# ESP32-S2 register map
Vendor: ESPRESSIF SYSTEMS (SHANGHAI) CO., LTD.; Series: ESP32 S-Series; File version: 20
CPU: Xtensa LX7 r0p0, little endian, no MPU, no FPU, 0 interrupt priority bits
Address unit: 32 bits
Registers are 32-bit, read-write, reset 0x0 unless marked. A register's access mark holds for its fields unless they carry their own. Offsets are from the block's base; [hi:lo] are bit positions; {n}, {i} and the like mark numbered series.

## RTC_CNTL — Real-Time Clock Control
Base 0x3F408000
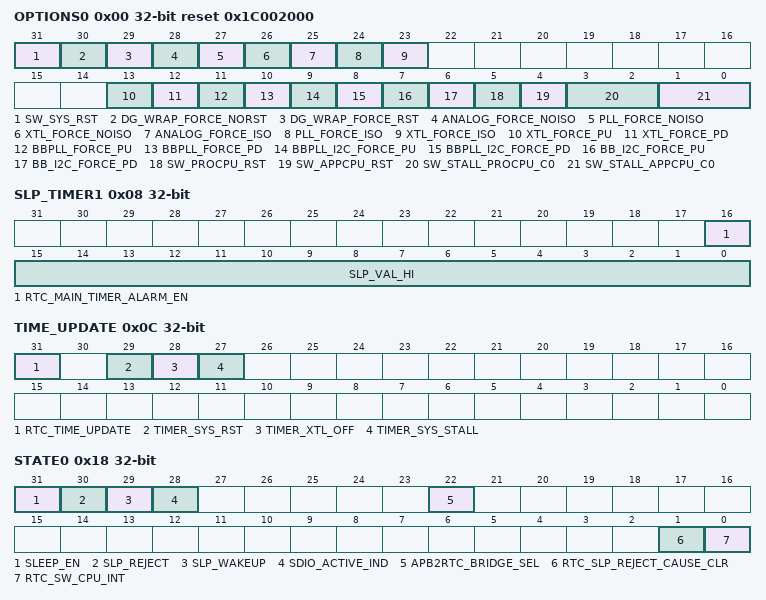
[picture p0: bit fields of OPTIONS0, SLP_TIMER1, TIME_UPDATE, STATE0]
0x00 OPTIONS0 access per field reset 0x1C002000 — Sets the power options of crystal and PLL clocks, and initiates reset by software
  [31] SW_SYS_RST wo — Set this bit to reset the system via SW.
  [30] DG_WRAP_FORCE_NORST rw — Set this bit to disable force reset to digital system in deep-sleep.
  [29] DG_WRAP_FORCE_RST rw — Set this bit to force reset the digital system in deep-sleep.
  [28] ANALOG_FORCE_NOISO rw
  [27] PLL_FORCE_NOISO rw
  [26] XTL_FORCE_NOISO rw
  [25] ANALOG_FORCE_ISO rw
  [24] PLL_FORCE_ISO rw
  [23] XTL_FORCE_ISO rw
  [13] XTL_FORCE_PU rw — Set this bit to FPU the crystal oscillator.
  [12] XTL_FORCE_PD rw — Set this bit to FPD the crystal oscillator.
  [11] BBPLL_FORCE_PU rw — Set this bit to FPU BB_PLL.
  [10] BBPLL_FORCE_PD rw — Set this bit to FPD BB_PLL.
  [9] BBPLL_I2C_FORCE_PU rw — Set this bit to FPU BB_PLL _I2C.
  [8] BBPLL_I2C_FORCE_PD rw — Set this bit to FPD BB_PLL _I2C.
  [7] BB_I2C_FORCE_PU rw — Set this bit to FPU BB_I2C.
  [6] BB_I2C_FORCE_PD rw — Set this bit to FPD BB_I2C.
  [5] SW_PROCPU_RST wo — Set this bit to reset the CPU by SW.
  [4] SW_APPCPU_RST wo — APP CPU SW reset. (Note, we don’t have APP CPU for ESP32-S2)
  [3:2] SW_STALL_PROCPU_C0 rw — When RTC_CNTL_REG_SW_STALL_PROCPU_C1 is configured to 0x21, setting this bit to 0x2 stalls the CPU by SW.
  [1:0] SW_STALL_APPCPU_C0 rw — {reg_sw_stall_appcpu_c1[5:0] , reg_sw_stall_appcpu_c0[1:0]} == 0x86 will stall APP CPU
0x04 SLP_TIMER0 — RTC timer threshold register 0
  [31:0] SLP_VAL_LO — Sets the lower 32 bits of the trigger threshold for the RTC timer.
0x08 SLP_TIMER1 access per field — RTC timer threshold register 1
  [16] RTC_MAIN_TIMER_ALARM_EN wo — Sets this bit to enable the timer alarm.
  [15:0] SLP_VAL_HI rw — Sets the higher 16 bits of the trigger threshold for the RTC timer.
0x0C TIME_UPDATE access per field — RTC timer update control register
  [31] RTC_TIME_UPDATE wo — Selects the triggering condition for the RTC timer. See details in Table 1-2.
  [29] TIMER_SYS_RST rw — Selects the triggering condition for the RTC timer. See details in Table 1-2.
  [28] TIMER_XTL_OFF rw — Selects the triggering condition for the RTC timer. See details in Table 1-2.
  [27] TIMER_SYS_STALL rw — Selects the triggering condition for the RTC timer. See details in Table 1-2.
0x10 TIME_LOW0 ro — Stores the lower 32 bits of RTC timer 0.
  [31:0] RTC_TIMER_VALUE0_LOW
0x14 TIME_HIGH0 ro — Stores the higher 16 bits of RTC timer 0
  [15:0] RTC_TIMER_VALUE0_HIGH — Stores the higher 16 bits of RTC timer 0.
0x18 STATE0 access per field — Configures the sleep / reject / wakeup state
  [31] SLEEP_EN rw — Sends the chip to sleep.
  [30] SLP_REJECT rw — Sleep reject bit.
  [29] SLP_WAKEUP rw — Sleep wakeup bit.
  [28] SDIO_ACTIVE_IND ro — Indicates the SDIO is active.
  [22] APB2RTC_BRIDGE_SEL rw — 1: APB to RTC using bridge 0: APB to RTC using sync
  [1] RTC_SLP_REJECT_CAUSE_CLR wo — Clears the RTC reject-to-sleep cause.
  [0] RTC_SW_CPU_INT wo — Sends a SW RTC interrupt to CPU.
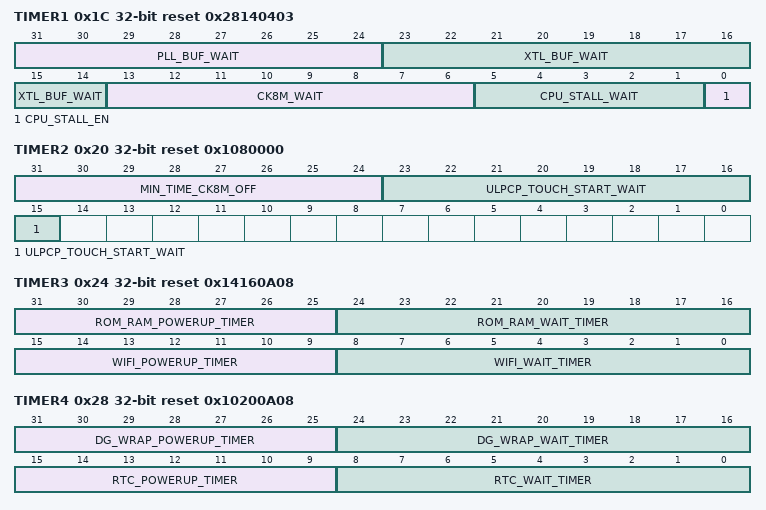
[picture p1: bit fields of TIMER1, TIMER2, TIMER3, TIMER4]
0x1C TIMER1 reset 0x28140403 — Configures CPU stall options
  [31:24] PLL_BUF_WAIT — Sets the PLL waiting cycle (using the RTC slow clock).
  [23:14] XTL_BUF_WAIT — Sets the XTAL waiting cycle (using the RTC slow clock).
  [13:6] CK8M_WAIT — Sets the 8 MHz clock waiting (using the RTC slow clock).
  [5:1] CPU_STALL_WAIT — Sets the CPU stall waiting cycle (using the RTC fast clock).
  [0] CPU_STALL_EN — Enables CPU stalling.
0x20 TIMER2 reset 0x1080000 — Configures RTC slow clock and touch controller
  [31:24] MIN_TIME_CK8M_OFF — Sets the minimal cycle for 8 MHz clock (using the RTC slow clock) when powered down.
  [23:15] ULPCP_TOUCH_START_WAIT — Sets the waiting cycle (using the RTC slow clock) before the ULP co-processor / touch controller start to work.
0x24 TIMER3 reset 0x14160A08 — configure some wait time for power on
  [31:25] ROM_RAM_POWERUP_TIMER, [24:16] ROM_RAM_WAIT_TIMER, [15:9] WIFI_POWERUP_TIMER, [8:0] WIFI_WAIT_TIMER
0x28 TIMER4 reset 0x10200A08 — configure some wait time for power on
  [31:25] DG_WRAP_POWERUP_TIMER, [24:16] DG_WRAP_WAIT_TIMER, [15:9] RTC_POWERUP_TIMER, [8:0] RTC_WAIT_TIMER
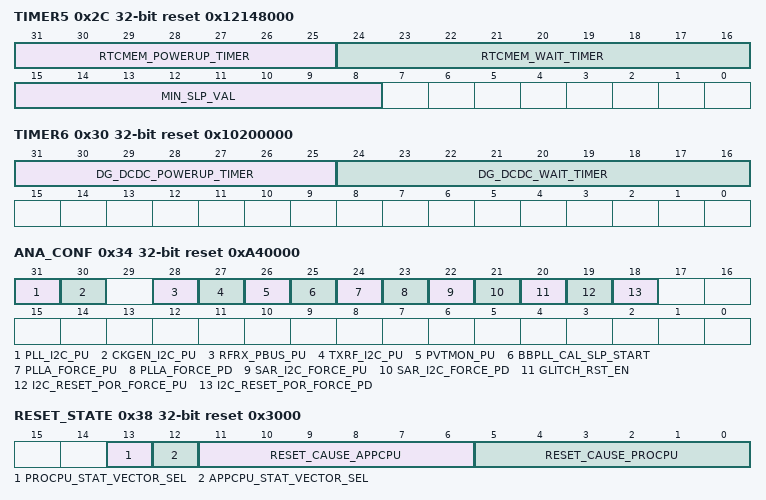
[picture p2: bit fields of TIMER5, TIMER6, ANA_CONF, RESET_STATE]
0x2C TIMER5 reset 0x12148000 — Configures the minimal sleep cycles
  [31:25] RTCMEM_POWERUP_TIMER
  [24:16] RTCMEM_WAIT_TIMER
  [15:8] MIN_SLP_VAL — Sets the minimal sleep cycles (using the RTC slow clock).
0x30 TIMER6 reset 0x10200000 — Configure minimal sleep cycles register
  [31:25] DG_DCDC_POWERUP_TIMER, [24:16] DG_DCDC_WAIT_TIMER
0x34 ANA_CONF reset 0xA40000 — Configures the power options for I2C and PLLA
  [31] PLL_I2C_PU — 1. PLL_I2C power up ,otherwise power down
  [30] CKGEN_I2C_PU — 1: CKGEN_I2C power up , otherwise power down
  [28] RFRX_PBUS_PU — 1: RFRX_PBUS power up , otherwise power down
  [27] TXRF_I2C_PU — 1: TXRF_I2C power up , otherwise power down
  [26] PVTMON_PU — 1: PVTMON power up , otherwise power down
  [25] BBPLL_CAL_SLP_START — start BBPLL calibration during sleep
  [24] PLLA_FORCE_PU — Sets this bit to FPU the PLLA.
  [23] PLLA_FORCE_PD — Sets this bit to FPD the PLLA.
  [22] SAR_I2C_FORCE_PU — Sets this bit to FPU the SAR_I2C.
  [21] SAR_I2C_FORCE_PD — Sets this bit to FPD the SAR_I2C.
  [20] GLITCH_RST_EN — Set this bit to enable a reset when the system detects a glitch.
  [19] I2C_RESET_POR_FORCE_PU — SLEEP_I2CPOR force pu
  [18] I2C_RESET_POR_FORCE_PD — SLEEP_I2CPOR force pd
0x38 RESET_STATE access per field reset 0x3000 — Indicates the CPU reset source. For more information about the reset cause, please refer to Table ef{table:resetreasons} in Chapter ef{module:ResetandClock} extit{ ameref{module:ResetandClock}}.
  [13] PROCPU_STAT_VECTOR_SEL rw — Selects the CPU state vector.
  [12] APPCPU_STAT_VECTOR_SEL rw — APP CPU state vector sel
  [11:6] RESET_CAUSE_APPCPU ro — reset cause of APP CPU
  [5:0] RESET_CAUSE_PROCPU ro — Stores the CPU reset cause.
0x3C WAKEUP_STATE reset 0x60000 — Wakeup bitmap enabling register
  [31:15] RTC_WAKEUP_ENA — Enables the wakeup bitmap.
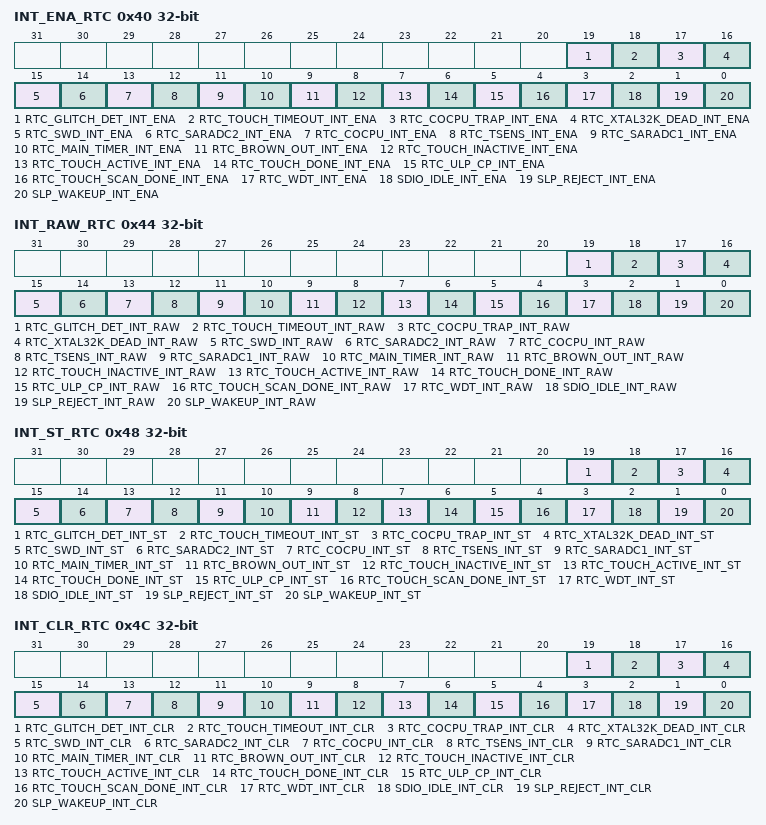
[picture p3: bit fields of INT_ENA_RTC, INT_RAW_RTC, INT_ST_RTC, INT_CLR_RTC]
0x40 INT_ENA_RTC — RTC interrupt enabling register
  [19] RTC_GLITCH_DET_INT_ENA — Enables interruption when a glitch is detected.
  [18] RTC_TOUCH_TIMEOUT_INT_ENA — Enables interruption when touch sensor times out.
  [17] RTC_COCPU_TRAP_INT_ENA — Enables interruption when the ULP-RISCV is trapped.
  [16] RTC_XTAL32K_DEAD_INT_ENA — Enables interruption when the 32 kHz crystal is dead.
  [15] RTC_SWD_INT_ENA — Enables the super watchdog interrupt.
  [14] RTC_SARADC2_INT_ENA — Enables the SAR ADC 2 interrupt.
  [13] RTC_COCPU_INT_ENA — Enables the ULP-RISCV interrupt.
  [12] RTC_TSENS_INT_ENA — Enables the touch sensor interrupt.
  [11] RTC_SARADC1_INT_ENA — Enables the SAR ADC 1 interrupt.
  [10] RTC_MAIN_TIMER_INT_ENA — Enables the RTC main timer interrupt.
  [9] RTC_BROWN_OUT_INT_ENA — Enables the brown out interrupt.
  [8] RTC_TOUCH_INACTIVE_INT_ENA — Enables interruption when a touch is released.
  [7] RTC_TOUCH_ACTIVE_INT_ENA — Enables interruption when a touch is detected.
  [6] RTC_TOUCH_DONE_INT_ENA — Enables interruption upon the completion of a single touch.
  [5] RTC_ULP_CP_INT_ENA — Enables the ULP co-processor interrupt.
  [4] RTC_TOUCH_SCAN_DONE_INT_ENA — Enables interruption upon the completion of a touch scanning.
  [3] RTC_WDT_INT_ENA — Enables the RTC watchdog interrupt.
  [2] SDIO_IDLE_INT_ENA — Enables interruption when the SDIO idles.
  [1] SLP_REJECT_INT_ENA — Enables interruption when the chip rejects to go to sleep.
  [0] SLP_WAKEUP_INT_ENA — Enables interruption when the chip wakes up from sleep.
0x44 INT_RAW_RTC ro — RTC interrupt raw register
  [19] RTC_GLITCH_DET_INT_RAW — Stores the raw interrupt triggered when a glitch is detected.
  [18] RTC_TOUCH_TIMEOUT_INT_RAW — Stores the raw interrupt triggered when touch sensor times out.
  [17] RTC_COCPU_TRAP_INT_RAW — Stores the raw interrupt triggered when the ULP-RISCV is trapped.
  [16] RTC_XTAL32K_DEAD_INT_RAW — Stores the raw interrupt triggered when the 32 kHz crystal is dead.
  [15] RTC_SWD_INT_RAW — Stores the raw super watchdog interrupt.
  [14] RTC_SARADC2_INT_RAW — Stores the raw SAR ADC 2 interrupt.
  [13] RTC_COCPU_INT_RAW — Stores the raw ULP-RISCV interrupt.
  [12] RTC_TSENS_INT_RAW — Stores the raw touch sensor interrupt.
  [11] RTC_SARADC1_INT_RAW — Stores the raw SAR ADC 1 interrupt.
  [10] RTC_MAIN_TIMER_INT_RAW — Stores the raw RTC main timer interrupt.
  [9] RTC_BROWN_OUT_INT_RAW — Stores the raw brown out interrupt.
  [8] RTC_TOUCH_INACTIVE_INT_RAW — Stores the raw interrupt triggered when a touch is released.
  [7] RTC_TOUCH_ACTIVE_INT_RAW — Stores the raw interrupt triggered when a touch is detected.
  [6] RTC_TOUCH_DONE_INT_RAW — Stores the raw interrupt triggered upon the completion of a single touch.
  [5] RTC_ULP_CP_INT_RAW — Stores the raw ULP co-processor interrupt.
  [4] RTC_TOUCH_SCAN_DONE_INT_RAW — Stores the raw interrupt triggered upon the completion of a touch scanning.
  [3] RTC_WDT_INT_RAW — Stores the raw RTC watchdog interrupt.
  [2] SDIO_IDLE_INT_RAW — Stores the raw interrupt triggered when the SDIO idles.
  [1] SLP_REJECT_INT_RAW — Stores the raw interrupt triggered when the chip rejects to go to sleep.
  [0] SLP_WAKEUP_INT_RAW — Stores the raw interrupt triggered when the chip wakes up from sleep.
0x48 INT_ST_RTC ro — RTC interrupt state register
  [19] RTC_GLITCH_DET_INT_ST — Stores the status of the interrupt triggered when a glitch is detected.
  [18] RTC_TOUCH_TIMEOUT_INT_ST — Stores the status of the interrupt triggered when touch sensor times out.
  [17] RTC_COCPU_TRAP_INT_ST — Stores the status of the interrupt triggered when the ULP-RISCV is trapped.
  [16] RTC_XTAL32K_DEAD_INT_ST — Stores the status of the interrupt triggered when the 32 kHz crystal is dead.
  [15] RTC_SWD_INT_ST — Stores the status of the super watchdog interrupt.
  [14] RTC_SARADC2_INT_ST — Stores the status of the SAR ADC 2 interrupt.
  [13] RTC_COCPU_INT_ST — Stores the status of the ULP-RISCV interrupt.
  [12] RTC_TSENS_INT_ST — Stores the status of the touch sensor interrupt.
  [11] RTC_SARADC1_INT_ST — Stores the status of the SAR ADC 1 interrupt.
  [10] RTC_MAIN_TIMER_INT_ST — Stores the status of the RTC main timer interrupt.
  [9] RTC_BROWN_OUT_INT_ST — Stores the status of the brown out interrupt.
  [8] RTC_TOUCH_INACTIVE_INT_ST — Stores the status of the interrupt triggered when a touch is released.
  [7] RTC_TOUCH_ACTIVE_INT_ST — Stores the status of the interrupt triggered when a touch is detected.
  [6] RTC_TOUCH_DONE_INT_ST — Stores the status of the interrupt triggered upon the completion of a single touch.
  [5] RTC_ULP_CP_INT_ST — Stores the status of the ULP co-processor interrupt.
  [4] RTC_TOUCH_SCAN_DONE_INT_ST — Stores the status of the interrupt triggered upon the completion of a touch scanning.
  [3] RTC_WDT_INT_ST — Stores the status of the RTC watchdog interrupt.
  [2] SDIO_IDLE_INT_ST — Stores the status of the interrupt triggered when the SDIO idles.
  [1] SLP_REJECT_INT_ST — Stores the status of the interrupt triggered when the chip rejects to go to sleep.
  [0] SLP_WAKEUP_INT_ST — Stores the status of the interrupt triggered when the chip wakes up from sleep.
0x4C INT_CLR_RTC wo — RTC interrupt clear register
  [19] RTC_GLITCH_DET_INT_CLR — Clears the interrupt triggered when a glitch is detected.
  [18] RTC_TOUCH_TIMEOUT_INT_CLR — Clears the interrupt triggered when touch sensor times out.
  [17] RTC_COCPU_TRAP_INT_CLR — Clears the interrupt triggered when the ULP-RISCV is trapped.
  [16] RTC_XTAL32K_DEAD_INT_CLR — Clears the interrupt triggered when the 32 kHz crystal is dead.
  [15] RTC_SWD_INT_CLR — Clears the super watchdog interrupt.
  [14] RTC_SARADC2_INT_CLR — Clears the SAR ADC 2 interrupt.
  [13] RTC_COCPU_INT_CLR — Clears the ULP-RISCV interrupt.
  [12] RTC_TSENS_INT_CLR — Clears the touch sensor interrupt.
  [11] RTC_SARADC1_INT_CLR — Clears the SAR ADC 1 interrupt.
  [10] RTC_MAIN_TIMER_INT_CLR — Clears the RTC main timer interrupt.
  [9] RTC_BROWN_OUT_INT_CLR — Clears the brown out interrupt.
  [8] RTC_TOUCH_INACTIVE_INT_CLR — Clears the interrupt triggered when a touch is released.
  [7] RTC_TOUCH_ACTIVE_INT_CLR — Clears the interrupt triggered when a touch is detected.
  [6] RTC_TOUCH_DONE_INT_CLR — Clears the interrupt triggered upon the completion of a single touch.
  [5] RTC_ULP_CP_INT_CLR — Enables the ULP co-processor interrupt.
  [4] RTC_TOUCH_SCAN_DONE_INT_CLR — Clears the interrupt triggered upon the completion of a touch scanning.
  [3] RTC_WDT_INT_CLR — Enables the RTC watchdog interrupt.
  [2] SDIO_IDLE_INT_CLR — Clears the interrupt triggered when the SDIO idles.
  [1] SLP_REJECT_INT_CLR — Clears the interrupt triggered when the chip rejects to go to sleep.
  [0] SLP_WAKEUP_INT_CLR — Clears the interrupt triggered when the chip wakes up from sleep.
{0x50+4i} STORE{i} (i=0..3) — Reservation register {i}
  [31:0] RTC_SCRATCH{i}
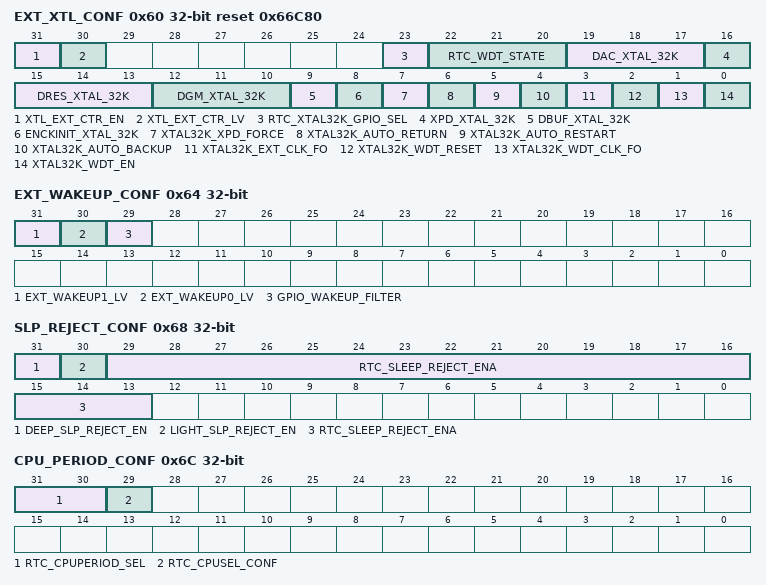
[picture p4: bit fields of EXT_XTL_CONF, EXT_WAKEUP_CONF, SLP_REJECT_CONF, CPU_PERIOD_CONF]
0x60 EXT_XTL_CONF access per field reset 0x66C80 — 32 kHz crystal oscillator configuration register
  [31] XTL_EXT_CTR_EN rw — Enables the GPIO to power down the crystal oscillator.
  [30] XTL_EXT_CTR_LV rw — 0: powers down XTAL at high level 1: powers down XTAL at low level
  [23] RTC_XTAL32K_GPIO_SEL rw — Selects the 32 kHz crystal clock. 0: selects the external 32 kHz clock. 1: selects clock from the RTC GPIO X32P_C.
  [22:20] RTC_WDT_STATE ro — Stores the status of the 32 kHz watchdog.
  [19:17] DAC_XTAL_32K rw
  [16] XPD_XTAL_32K rw
  [15:13] DRES_XTAL_32K rw
  [12:10] DGM_XTAL_32K rw — xtal_32k gm control
  [9] DBUF_XTAL_32K rw — 0: single-end buffer 1: differential buffer
  [8] ENCKINIT_XTAL_32K rw — Applies an internal clock to help the 32 kHz crystal to start.
  [7] XTAL32K_XPD_FORCE rw — Set 1 to allow the software to FPD the 32 kHz crystal. Set 0 to allow the FSM to FPD the 32 kHz crystal. (R/W)
  [6] XTAL32K_AUTO_RETURN rw — Set this bit to switch back to 32 kHz crystal when the 32 kHz crystal is restarted.
  [5] XTAL32K_AUTO_RESTART rw — Set this bit to restart the 32 kHz crystal automatically when the 32 kHz crystal is dead.
  [4] XTAL32K_AUTO_BACKUP rw — Set this bit to switch to the backup clock when the 32 kHz crystal is dead.
  [3] XTAL32K_EXT_CLK_FO rw — Set this bit to FPU the external clock of 32 kHz crystal.
  [2] XTAL32K_WDT_RESET rw — Set this bit to reset the 32 kHz crystal watchdog by SW.
  [1] XTAL32K_WDT_CLK_FO rw — Set this bit to FPU the 32 kHz crystal watchdog clock.
  [0] XTAL32K_WDT_EN rw — Set this bit to enable the 32 kHz crystal watchdog.
0x64 EXT_WAKEUP_CONF — GPIO wakeup configuration register
  [31] EXT_WAKEUP1_LV — 0: external wakeup 1 at low level 1: external wakeup 1 at high level
  [30] EXT_WAKEUP0_LV — 0: external wakeup 0 at low level 1: external wakeup 0 at high level
  [29] GPIO_WAKEUP_FILTER — Set this bit to enable the GPIO wakeup event filter.
0x68 SLP_REJECT_CONF — Configures sleep / reject options
  [31] DEEP_SLP_REJECT_EN — Set this bit to enable reject-to-deep-sleep.
  [30] LIGHT_SLP_REJECT_EN — Set this bit to enable reject-to-light-sleep.
  [29:13] RTC_SLEEP_REJECT_ENA — Set this bit to enable reject-to-sleep.
0x6C CPU_PERIOD_CONF — CPU sel option
  [31:30] RTC_CPUPERIOD_SEL
  [29] RTC_CPUSEL_CONF — CPU sel option
0x70 SDIO_ACT_CONF — configure sdio active register
  [31:22] SDIO_ACT_DNUM — configure sdio act dnum
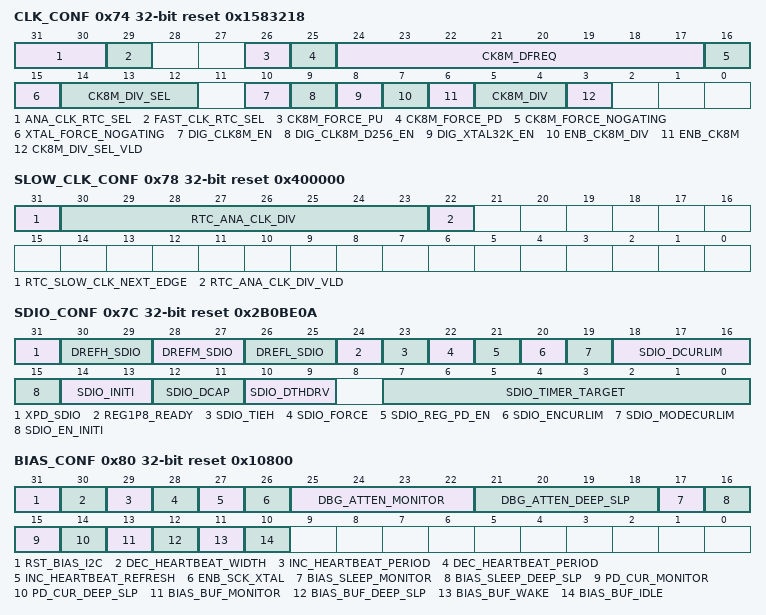
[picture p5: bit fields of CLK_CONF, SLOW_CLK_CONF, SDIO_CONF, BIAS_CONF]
0x74 CLK_CONF reset 0x1583218 — RTC clock configuration register
  [31:30] ANA_CLK_RTC_SEL — Set this bit to select the RTC slow clock. 0: 90K rtc_clk 1: 32k XTAL 2: 8md256.
  [29] FAST_CLK_RTC_SEL — Set this bit to select the RTC fast clock. 0: XTAL div 4, 1: CK8M.
  [26] CK8M_FORCE_PU — Set this bit to FPU the 8 MHz clock.
  [25] CK8M_FORCE_PD — Set this bit to FPD the 8 MHz clock.
  [24:17] CK8M_DFREQ
  [16] CK8M_FORCE_NOGATING — Set this bit to disable force gating to 8 MHz crystal during sleep.
  [15] XTAL_FORCE_NOGATING — Set this bit to force no gating to crystal during sleep
  [14:12] CK8M_DIV_SEL — Stores the 8 MHz divider, which is reg_ck8m_div_sel + 1
  [10] DIG_CLK8M_EN — Set this bit to enable 8 MHz clock for the digital core.
  [9] DIG_CLK8M_D256_EN — Set this bit to enable CK8M_D256_OUT clock for the digital core.
  [8] DIG_XTAL32K_EN — Set this bit to enable CK_XTAL_32K clock for the digital core.
  [7] ENB_CK8M_DIV — Selects the CK8M_D256_OUT. 1: CK8M 0: CK8M divided by 256.
  [6] ENB_CK8M — Set this bit to disable CK8M and CK8M_D256_OUT.
  [5:4] CK8M_DIV — Set the CK8M_D256_OUT divider. 00: divided by 128 01: divided by 256 10: divided by 512 11: divided by 1024.
  [3] CK8M_DIV_SEL_VLD — Synchronizes the reg_ck8m_div_sel. Not that you have to invalidate the bus before switching clock, and validate the new clock.
0x78 SLOW_CLK_CONF reset 0x400000 — RTC slow clock configuration register
  [31] RTC_SLOW_CLK_NEXT_EDGE
  [30:23] RTC_ANA_CLK_DIV — Set the rtc_clk divider.
  [22] RTC_ANA_CLK_DIV_VLD — Synchronizes the reg_rtc_ana_clk_div bus. Note that you have to invalidate the bus before switching clock, and validate the new clock.
0x7C SDIO_CONF access per field reset 0x2B0BE0A — configure vddsdio register
  [31] XPD_SDIO rw — SW option for XPD_VOOSDIO. Only active when reg_sdio_force = 1
  [30:29] DREFH_SDIO rw — SW option for DREFH_SDIO. Only active when reg_sdio_force = 1
  [28:27] DREFM_SDIO rw — SW option for DREFM_SDIO. Only active when reg_sdio_force = 1
  [26:25] DREFL_SDIO rw — SW option for DREFL_SDIO. Only active when reg_sdio_force = 1
  [24] REG1P8_READY ro — read only register for REG1P8_READY
  [23] SDIO_TIEH rw — SW option for SDIO_TIEH. Only active when reg_sdio_force = 1
  [22] SDIO_FORCE rw — 1: use SW option to control SDIO_REG 0: use state machine
  [21] SDIO_REG_PD_EN rw — power down SDIO_REG in sleep. Only active when reg_sdio_force = 0
  [20] SDIO_ENCURLIM rw — enable current limit
  [19] SDIO_MODECURLIM rw — select current limit mode
  [18:16] SDIO_DCURLIM rw — tune current limit threshold when tieh = 0. About 800mA/(8+d)
  [15] SDIO_EN_INITI rw — 0 to set init[1:0]=0
  [14:13] SDIO_INITI rw — add resistor from ldo output to ground. 0: no res 1: 6k 2: 4k 3: 2k
  [12:11] SDIO_DCAP rw — ability to prevent LDO from overshoot
  [10:9] SDIO_DTHDRV rw — Tieh = 1 mode drive ability. Initially set to 0 to limit charge current set to 3 after several us.
  [7:0] SDIO_TIMER_TARGET rw — timer count to apply reg_sdio_dcap after sdio power on
0x80 BIAS_CONF reset 0x10800 — configure power register
  [31] RST_BIAS_I2C
  [30] DEC_HEARTBEAT_WIDTH
  [29] INC_HEARTBEAT_PERIOD
  [28] DEC_HEARTBEAT_PERIOD
  [27] INC_HEARTBEAT_REFRESH
  [26] ENB_SCK_XTAL
  [25:22] DBG_ATTEN_MONITOR — DBG_ATTEN when rtc in monitor state
  [21:18] DBG_ATTEN_DEEP_SLP — DBG_ATTEN when rtc in sleep state
  [17] BIAS_SLEEP_MONITOR — bias_sleep when rtc in monitor state
  [16] BIAS_SLEEP_DEEP_SLP — bias_sleep when rtc in sleep_state
  [15] PD_CUR_MONITOR — xpd cur when rtc in monitor state
  [14] PD_CUR_DEEP_SLP — xpd cur when rtc in sleep_state
  [13] BIAS_BUF_MONITOR — open bias buf when rtc in monitor state
  [12] BIAS_BUF_DEEP_SLP — open bias buf when rtc in deep sleep
  [11] BIAS_BUF_WAKE — open bias buf when rtc in wakeup
  [10] BIAS_BUF_IDLE — open bias buf when system in active
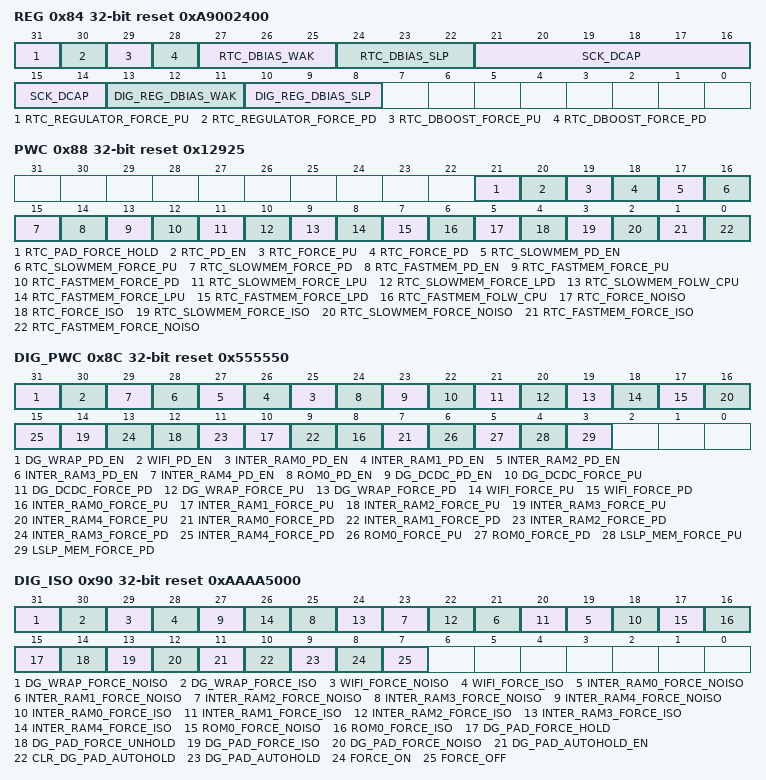
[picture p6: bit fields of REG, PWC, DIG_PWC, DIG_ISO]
0x84 REG reset 0xA9002400 — RTC/DIG regulator configuration register
  [31] RTC_REGULATOR_FORCE_PU — Set this bit to FPU the RTC_REG.
  [30] RTC_REGULATOR_FORCE_PD — Set this bit to FPD the RTC_REG, which means decreasing its voltage to 0.8 V or lower.
  [29] RTC_DBOOST_FORCE_PU — RTC_DBOOST force power up
  [28] RTC_DBOOST_FORCE_PD — RTC_DBOOST force power down
  [27:25] RTC_DBIAS_WAK — Configures the regulation factor for the low-power voltage regulator when the CPU is in active status.
  [24:22] RTC_DBIAS_SLP — Configures the regulation factor for the low-power voltage regulator when the CPU is in sleep status.
  [21:14] SCK_DCAP — Configures the frequency of the RTC clocks.
  [13:11] DIG_REG_DBIAS_WAK — Configures the regulation factor for the digital system voltage regulator when the CPU is in active status.
  [10:8] DIG_REG_DBIAS_SLP — Configures the regulation factor for the digital system voltage regulator when the CPU is in sleep status.
0x88 PWC reset 0x12925 — RTC power configuraiton register
  [21] RTC_PAD_FORCE_HOLD — Set this bit the force hold the RTC GPIOs.
  [20] RTC_PD_EN — Set this bit to enable PD for the RTC peripherals in sleep.
  [19] RTC_FORCE_PU — Set this bit to FPU the RTC peripherals.
  [18] RTC_FORCE_PD — Set this bit to FPD the RTC peripherals.
  [17] RTC_SLOWMEM_PD_EN — Set this bit to enable PD for the RTC slow memory in sleep.
  [16] RTC_SLOWMEM_FORCE_PU — Set this bit to FPU the RTC slow memory.
  [15] RTC_SLOWMEM_FORCE_PD — Set this bit to FPD the RTC slow memory.
  [14] RTC_FASTMEM_PD_EN — Set this bit to enable PD for the RTC fast memory in sleep.
  [13] RTC_FASTMEM_FORCE_PU — Set this bit to FPU the RTC fast memory.
  [12] RTC_FASTMEM_FORCE_PD — Set this bit to FPD the RTC fast memory.
  [11] RTC_SLOWMEM_FORCE_LPU — Set this bit to force retain the RTC slow memory.
  [10] RTC_SLOWMEM_FORCE_LPD — Set this bit to force not retain the RTC slow memory.
  [9] RTC_SLOWMEM_FOLW_CPU — Set 1 to FPD the RTC slow memory when the CPU is powered down. Set 0 to FPD the RTC slow memory when the RTC main state machine is powered down.
  [8] RTC_FASTMEM_FORCE_LPU — Set this bit to force retain the RTC fast memory.
  [7] RTC_FASTMEM_FORCE_LPD — Set this bit to force not retain the RTC fast memory.
  [6] RTC_FASTMEM_FOLW_CPU — Set 1 to FPD the RTC fast memory when the CPU is powered down. Set 0 to FPD the RTC fast memory when the RTC main state machine is powered down.
  [5] RTC_FORCE_NOISO — Set this bit to disable the force isolation to the RTC peripherals.
  [4] RTC_FORCE_ISO — Set this bit to force isolate the RTC peripherals.
  [3] RTC_SLOWMEM_FORCE_ISO — Set this bit to force isolate the RTC slow memory.
  [2] RTC_SLOWMEM_FORCE_NOISO — Set this bit to disable the force isolation to the RTC slow memory.
  [1] RTC_FASTMEM_FORCE_ISO — Set this bit to force isolate the RTC fast memory.
  [0] RTC_FASTMEM_FORCE_NOISO — Set this bit to disable the force isolation to the RTC fast memory.
0x8C DIG_PWC reset 0x555550 — Digital system power configuraiton register
  [31] DG_WRAP_PD_EN — Set this bit to enable PD for the digital system in sleep.
  [30] WIFI_PD_EN — Set this bit to enable PD for the Wi-Fi circuit in sleep.
  [n+25] INTER_RAM{n}_PD_EN (n=0..4) — enable power down internal SRAM {n} in sleep
  [24] ROM0_PD_EN — enable power down ROM in sleep
  [23] DG_DCDC_PD_EN — Set this bit to enable PD for the DC-DC convertor in the digital system.
  [22] DG_DCDC_FORCE_PU — Set this bit to FPU the DC-DC convertor in the digital system.
  [21] DG_DCDC_FORCE_PD — Set this bit to FPD the DC-DC convertor in the digital system.
  [20] DG_WRAP_FORCE_PU — Set this bit to FPD the DC-DC convertor in the digital system.
  [19] DG_WRAP_FORCE_PD — Set this bit to FPD the digital system.
  [18] WIFI_FORCE_PU — Set this bit to FPU the Wi-Fi circuit.
  [17] WIFI_FORCE_PD — Set this bit to FPD the Wi-Fi circuit.
  [2n+8] INTER_RAM{n}_FORCE_PU (n=0..4) — internal SRAM {n} force power up
  [2n+7] INTER_RAM{n}_FORCE_PD (n=0..4) — internal SRAM {n} force power down
  [6] ROM0_FORCE_PU — ROM force power up
  [5] ROM0_FORCE_PD — ROM force power down
  [4] LSLP_MEM_FORCE_PU — Set this bit to FPU the memories in the digital system.
  [3] LSLP_MEM_FORCE_PD — Set this bit to FPD the memories in the digital system in sleep.
0x90 DIG_ISO access per field reset 0xAAAA5000 — Digital system ISO configuration register
  [31] DG_WRAP_FORCE_NOISO rw — Set this bit to disable the force isolation to the digital system.
  [30] DG_WRAP_FORCE_ISO rw — Set this bit to force isolate the digital system.
  [29] WIFI_FORCE_NOISO rw — Set this bit to disable the force isolation to the Wi-Fi circuits.
  [28] WIFI_FORCE_ISO rw — Set this bit to force isolate the Wi-Fi circuits.
  [2n+19] INTER_RAM{n}_FORCE_NOISO rw (n=0..4) — internal SRAM {n} force no ISO
  [2n+18] INTER_RAM{n}_FORCE_ISO rw (n=0..4) — internal SRAM {n} force ISO
  [17] ROM0_FORCE_NOISO rw — ROM force no ISO
  [16] ROM0_FORCE_ISO rw — ROM force ISO
  [15] DG_PAD_FORCE_HOLD rw — Set this bit the force hold the digital GPIOs.
  [14] DG_PAD_FORCE_UNHOLD rw — Set this bit the force unhold the digital GPIOs.
  [13] DG_PAD_FORCE_ISO rw — Set this bit to force isolate the digital GPIOs.
  [12] DG_PAD_FORCE_NOISO rw — Set this bit to disable the force isolation to the digital GPIOs.
  [11] DG_PAD_AUTOHOLD_EN rw — Se this bit to allow the digital GPIOs to enter the autohold status.
  [10] CLR_DG_PAD_AUTOHOLD wo — Se this bit to clear the auto-hold enabler for the digital GPIOs.
  [9] DG_PAD_AUTOHOLD ro — Indicates the auto-hold status of the digital GPIOs.
  [8] FORCE_ON rw
  [7] FORCE_OFF rw
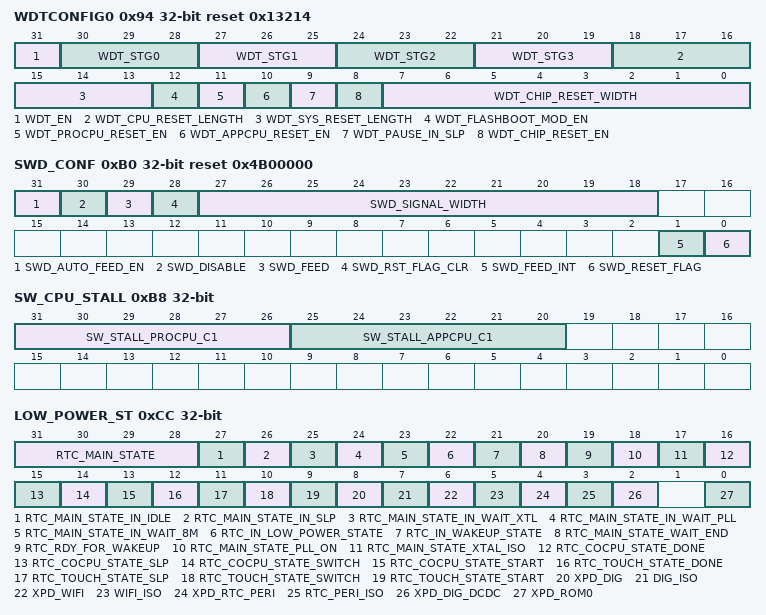
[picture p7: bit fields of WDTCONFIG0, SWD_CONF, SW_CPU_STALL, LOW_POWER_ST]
0x94 WDTCONFIG0 reset 0x13214 — RTC watchdog configuration register
  [31] WDT_EN — Set this bit to enable the RTC watchdog.
  [30-3n:28-3n] WDT_STG{n} (n=0..3) — 1: enable at the interrupt stage 2: enable at the CPU stage 3: enable at the system stage 4: enable at the system and RTC stage.
  [18:16] WDT_CPU_RESET_LENGTH — Sets the length of the CPU reset counter.
  [15:13] WDT_SYS_RESET_LENGTH — Sets the length of the system reset counter.
  [12] WDT_FLASHBOOT_MOD_EN — Set this bit to enable watchdog when the chip boots from flash.
  [11] WDT_PROCPU_RESET_EN — Set this bit to allow the watchdog to be able to reset CPU.
  [10] WDT_APPCPU_RESET_EN — enable WDT reset APP CPU
  [9] WDT_PAUSE_IN_SLP — Set this bit to pause the watchdog in sleep.
  [8] WDT_CHIP_RESET_EN — wdt reset whole chip enable
  [7:0] WDT_CHIP_RESET_WIDTH — chip reset siginal pulse width
0x98 WDTCONFIG1 reset 0x30D40 — Configures the hold time of RTC watchdog at level 1
  [31:0] WDT_STG0_HOLD — Configures the hold time of RTC watchdog at level 1.
0x9C WDTCONFIG2 reset 0x13880 — Configures the hold time of RTC watchdog at level 2
  [31:0] WDT_STG1_HOLD — Configures the hold time of RTC watchdog at level 2.
0xA0 WDTCONFIG3 reset 0xFFF — Configures the hold time of RTC watchdog at level 3
  [31:0] WDT_STG2_HOLD — Configures the hold time of RTC watchdog at level 3.
0xA4 WDTCONFIG4 reset 0xFFF — Configures the hold time of RTC watchdog at level 4
  [31:0] WDT_STG3_HOLD — Configures the hold time of RTC watchdog at level 4.
0xA8 WDTFEED wo — RTC watchdog SW feed configuration register
  [31] RTC_WDT_FEED — Set 1 to feed the RTC watchdog.
0xAC WDTWPROTECT reset 0x50D83AA1 — RTC watchdog write protection configuration register
  [31:0] WDT_WKEY — Sets the write protection key of the watchdog.
0xB0 SWD_CONF access per field reset 0x4B00000 — Super watchdog configuration register
  [31] SWD_AUTO_FEED_EN rw — Set this bit to enable automatic watchdog feeding upon interrupts.
  [30] SWD_DISABLE rw — Set this bit to disable super watchdog.
  [29] SWD_FEED wo — Set to feed the super watchdog via SW.
  [28] SWD_RST_FLAG_CLR wo — Set to reset the super watchdog reset flag.
  [27:18] SWD_SIGNAL_WIDTH rw — Adjusts the signal width sent to the super watchdog.
  [1] SWD_FEED_INT ro — Receiving this interrupt leads to feeding the super watchdog via SW.
  [0] SWD_RESET_FLAG ro — Indicates the super watchdog reset flag.
0xB4 SWD_WPROTECT reset 0x8F1D312A — Super watchdog write protection configuration register
  [31:0] SWD_WKEY — Sets the write protection key of the super watchdog.
0xB8 SW_CPU_STALL — CPU stall configuration register
  [31:26] SW_STALL_PROCPU_C1 — Set this bit to allow the SW to be able to send the CPU into stalling.
  [25:20] SW_STALL_APPCPU_C1 — {reg_sw_stall_appcpu_c1[5:0] reg_sw_stall_appcpu_c0[1:0]} == 0x86 will stall APP CPU
{0xAC+4i} STORE{i} (i=4..7) — Reservation register {i}
  [31:0] RTC_SCRATCH{i} — Reservation register {i}.
0xCC LOW_POWER_ST ro — RTC main state machine status register
  [31:28] RTC_MAIN_STATE — rtc main state machine status
  [27] RTC_MAIN_STATE_IN_IDLE — rtc main state machine is in idle state
  [26] RTC_MAIN_STATE_IN_SLP — rtc main state machine is in sleep state
  [25] RTC_MAIN_STATE_IN_WAIT_XTL — rtc main state machine is in wait xtal state
  [24] RTC_MAIN_STATE_IN_WAIT_PLL — rtc main state machine is in wait pll state
  [23] RTC_MAIN_STATE_IN_WAIT_8M — rtc main state machine is in wait 8m state
  [22] RTC_IN_LOW_POWER_STATE — rtc main state machine is in the states of low power
  [21] RTC_IN_WAKEUP_STATE — rtc main state machine is in the states of wakeup process
  [20] RTC_MAIN_STATE_WAIT_END — rtc main state machine has been waited for some cycles
  [19] RTC_RDY_FOR_WAKEUP — Indicates the RTC is ready to be triggered by any wakeup source.
  [18] RTC_MAIN_STATE_PLL_ON — rtc main state machine is in states that pll should be running
  [17] RTC_MAIN_STATE_XTAL_ISO — no use any more
  [16] RTC_COCPU_STATE_DONE — ulp/cocpu is done
  [15] RTC_COCPU_STATE_SLP — ulp/cocpu is in sleep state
  [14] RTC_COCPU_STATE_SWITCH — ulp/cocpu is about to working. Switch rtc main state
  [13] RTC_COCPU_STATE_START — ulp/cocpu should start to work
  [12] RTC_TOUCH_STATE_DONE — touch is done
  [11] RTC_TOUCH_STATE_SLP — touch is in sleep state
  [10] RTC_TOUCH_STATE_SWITCH — touch is about to working. Switch rtc main state
  [9] RTC_TOUCH_STATE_START — touch should start to work
  [8] XPD_DIG — digital wrap power down
  [7] DIG_ISO — digital wrap iso
  [6] XPD_WIFI — wifi wrap power down
  [5] WIFI_ISO
  [4] XPD_RTC_PERI — rtc peripheral power down
  [3] RTC_PERI_ISO — rtc peripheral iso
  [2] XPD_DIG_DCDC — External DCDC power down
  [0] XPD_ROM0 — rom0 power down
0xD0 DIAG0 ro — debug register
  [31:0] RTC_LOW_POWER_DIAG1
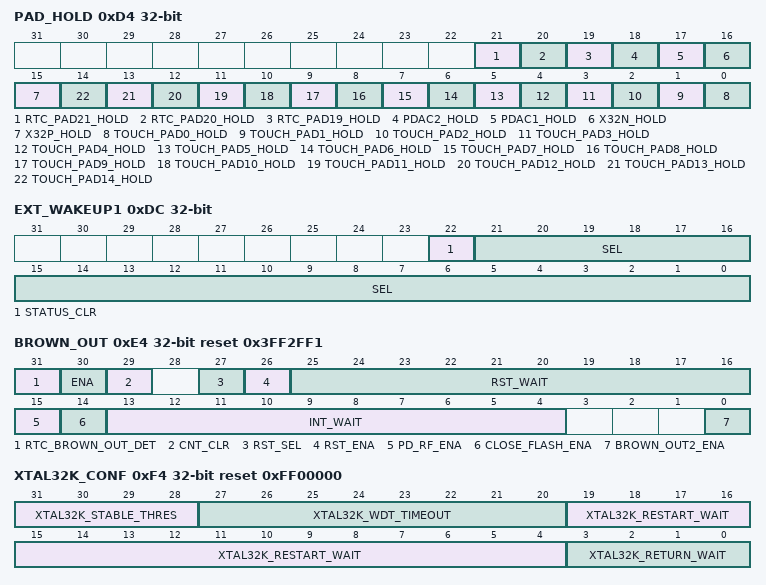
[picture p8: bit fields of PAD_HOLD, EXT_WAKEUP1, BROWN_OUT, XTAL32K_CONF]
0xD4 PAD_HOLD — Configures the hold options for RTC GPIOs
  [21] RTC_PAD21_HOLD — Sets the RTG GPIO 21 to hold.
  [20] RTC_PAD20_HOLD — Sets the RTG GPIO 20 to hold.
  [19] RTC_PAD19_HOLD — Sets the RTG GPIO 19 to hold.
  [18] PDAC2_HOLD — Sets the pdac2 to hold.
  [17] PDAC1_HOLD — Sets the pdac1 to hold.
  [16] X32N_HOLD — Sets the x32n to hold.
  [15] X32P_HOLD — Sets the x32p to hold.
  [n] TOUCH_PAD{n}_HOLD (n=0..14) — Sets the touch GPIO {n} to hold.
0xD8 DIG_PAD_HOLD — Configures the hold option for digital GPIOs
  [31:0] DIG_PAD_HOLD — Set GPIO 21 to GPIO 45 to hold. (See bitmap to locate any GPIO).
0xDC EXT_WAKEUP1 access per field — EXT1 wakeup configuration register
  [22] STATUS_CLR wo — Clears the EXT1 wakeup status.
  [21:0] SEL rw — Selects a RTC GPIO to be the EXT1 wakeup source.
0xE0 EXT_WAKEUP1_STATUS ro — EXT1 wakeup source register
  [21:0] EXT_WAKEUP1_STATUS — Indicates the EXT1 wakeup status.
0xE4 BROWN_OUT access per field reset 0x3FF2FF1 — Brownout configuration register
  [31] RTC_BROWN_OUT_DET ro — Indicates the status of the brown-out signal.
  [30] ENA rw — Set this bit to enable brown-out detection.
  [29] CNT_CLR wo — Clears the brown-out counter.
  [27] RST_SEL rw — Selects the reset type when a brown-out happens. 1: chip reset 0: system reset.
  [26] RST_ENA rw — Enables to reset brown-out.
  [25:16] RST_WAIT rw — Configures the waiting cycle before the reset after a brown-out.
  [15] PD_RF_ENA rw — Set this bit to enable PD the RF circuits when a brown-out happens.
  [14] CLOSE_FLASH_ENA rw — Set this bit to enable PD the flash when a brown-out happens.
  [13:4] INT_WAIT rw — Configures the waiting cycle before sending an interrupt.
  [0] BROWN_OUT2_ENA rw — Enables the brown_out2 to initiate a chip reset.
0xE8 TIME_LOW1 ro — Stores the lower 32 bits of RTC timer 1
  [31:0] RTC_TIMER_VALUE1_LOW — Stores the lower 32 bits of RTC timer 1.
0xEC TIME_HIGH1 ro — Stores the higher 16 bits of RTC timer 1
  [15:0] RTC_TIMER_VALUE1_HIGH — Stores the higher 16 bits of RTC timer.
0xF0 XTAL32K_CLK_FACTOR — Configures the divider factor for the backup clock of 32 kHz crystal oscillator
  [31:0] XTAL32K_CLK_FACTOR — Configures the divider factor for the 32 kHz crystal oscillator.
0xF4 XTAL32K_CONF reset 0xFF00000 — 32 kHz crystal oscillator configuration register
  [31:28] XTAL32K_STABLE_THRES — Defines the maximum allowed restarting period, within which the 32 kHz crystal oscillator can be regarded as stable.
  [27:20] XTAL32K_WDT_TIMEOUT — Defines the maximum waiting period for clock detection. If no clock is detected after this period, the 32 kHz crystal oscillator can be regarded as dead.
  [19:4] XTAL32K_RESTART_WAIT — Defines the maximum waiting cycle before restarting the 32 kHz crystal oscillator.
  [3:0] XTAL32K_RETURN_WAIT — Defines the waiting cycles before returning to the normal 32 kHz crystal oscillator.
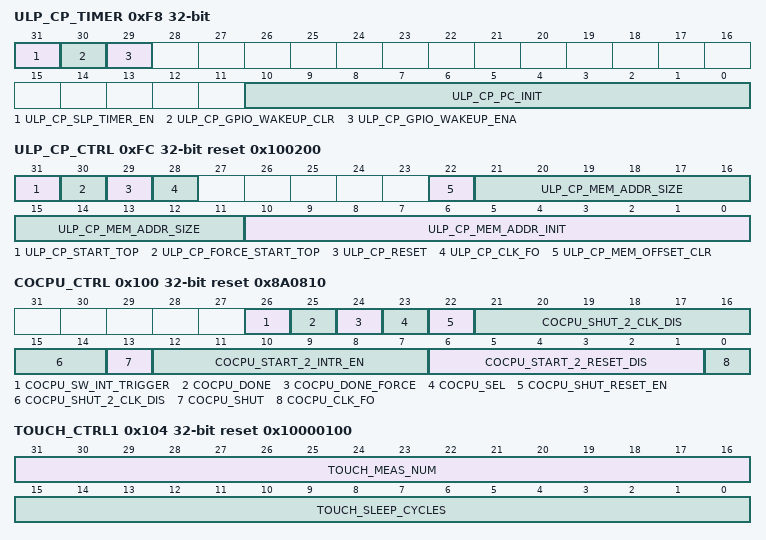
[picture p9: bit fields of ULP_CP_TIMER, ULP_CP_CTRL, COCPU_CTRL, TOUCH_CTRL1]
0xF8 ULP_CP_TIMER access per field — Configure coprocessor timer
  [31] ULP_CP_SLP_TIMER_EN rw — ULP coprocessor timer enable bit. 0: Disable hardware Timer. 1: Enable hardware timer
  [30] ULP_CP_GPIO_WAKEUP_CLR wo — Disable the option of ULP coprocessor woken up by RTC GPIO
  [29] ULP_CP_GPIO_WAKEUP_ENA rw — Enable the option of ULP coprocessor woken up by RTC GPIO
  [10:0] ULP_CP_PC_INIT rw — ULP coprocessor PC initial address
0xFC ULP_CP_CTRL access per field reset 0x100200 — ULP-FSM configuration register
  [31] ULP_CP_START_TOP rw — Write 1 to start ULP-FSM
  [30] ULP_CP_FORCE_START_TOP rw — Write 1 to start ULP-FSM by software
  [29] ULP_CP_RESET rw — ULP-FSM clock software reset
  [28] ULP_CP_CLK_FO rw — ULP-FSM clock force on
  [22] ULP_CP_MEM_OFFSET_CLR wo
  [21:11] ULP_CP_MEM_ADDR_SIZE rw
  [10:0] ULP_CP_MEM_ADDR_INIT rw
0x100 COCPU_CTRL access per field reset 0x8A0810 — ULP-RISCV configuration register
  [26] COCPU_SW_INT_TRIGGER wo — Trigger ULP-RISCV register interrupt
  [25] COCPU_DONE rw — DONE signal. Write 1 to this bit, ULP-RISCV will go to HALT and the timer starts counting
  [24] COCPU_DONE_FORCE rw — 0: select ULP-FSM DONE signal. 1: select ULP-RISCV DONE signal
  [23] COCPU_SEL rw — 0: select ULP-RISCV. 1: select ULP-FSM
  [22] COCPU_SHUT_RESET_EN rw — This bit is used to reset ULP-RISCV
  [21:14] COCPU_SHUT_2_CLK_DIS rw — Time from shut down ULP-RISCV to disable clock
  [13] COCPU_SHUT rw — Shut down ULP-RISCV
  [12:7] COCPU_START_2_INTR_EN rw — Time from ULP-RISCV startup to send out RISCV_START_INT interrupt
  [6:1] COCPU_START_2_RESET_DIS rw — Time from ULP-RISCV startup to pull down reset
  [0] COCPU_CLK_FO rw — ULP-RISCV clock force on
0x104 TOUCH_CTRL1 reset 0x10000100 — Touch control register
  [31:16] TOUCH_MEAS_NUM — Configure measurement length (in 8 MHz), i.e., charge/discharge times.
  [15:0] TOUCH_SLEEP_CYCLES — Set sleep cycles for touch timer.
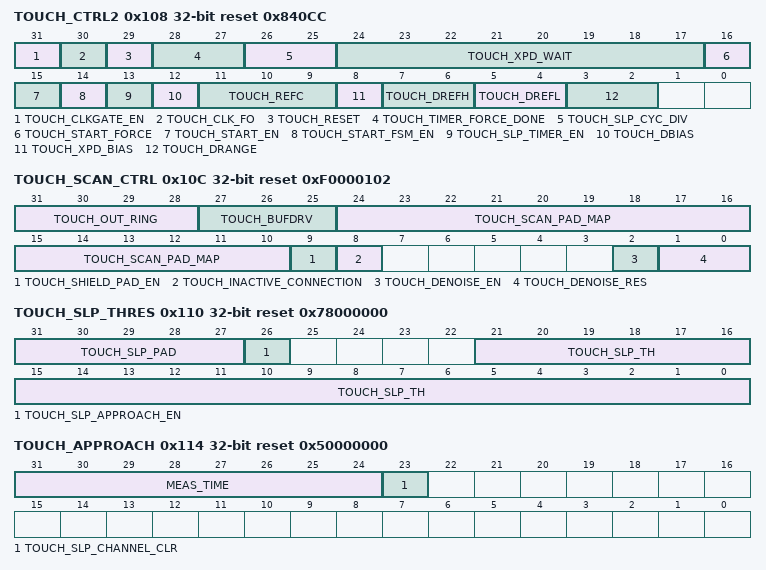
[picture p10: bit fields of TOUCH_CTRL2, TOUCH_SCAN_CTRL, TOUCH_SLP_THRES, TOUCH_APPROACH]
0x108 TOUCH_CTRL2 reset 0x840CC — Touch control register
  [31] TOUCH_CLKGATE_EN — Touch clock enable bit.
  [30] TOUCH_CLK_FO — Touch clock force on.
  [29] TOUCH_RESET — Reset TOUCH FSM via software.
  [28:27] TOUCH_TIMER_FORCE_DONE — Force touch timer done.
  [26:25] TOUCH_SLP_CYC_DIV — When a touch pad is active, sleep cycle could be divided by this number.
  [24:17] TOUCH_XPD_WAIT — The waiting cycles (in 8MHz) between TOUCH_START and TOUCH_XPD.
  [16] TOUCH_START_FORCE — 0: Start the Touch FSM by timer. 1: Start Touch FSM by software.
  [15] TOUCH_START_EN — 1: Start the Touch FSM, only valid when RTC_CNTL_TOUCH_START_FORCE = 1.
  [14] TOUCH_START_FSM_EN — 0: TOUCH_START and TOUCH_XPD are controlled by soft- ware. 1: TOUCH_START and TOUCH_XPD are controlled by the Touch FSM.
  [13] TOUCH_SLP_TIMER_EN — Touch timer enable bit.
  [12] TOUCH_DBIAS — 0: Use bandgap bias. 1: Use self bias.
  [11:9] TOUCH_REFC — Touch pad 0 reference capacitance.
  [8] TOUCH_XPD_BIAS — TOUCH BIAS power switch.
  [7:6] TOUCH_DREFH — TOUCH reference voltage high. 0: 2.4 V 1: 2.5 V 2: 2.6 V 3: 2.7 V.
  [5:4] TOUCH_DREFL — TOUCH reference voltage low. 0: 0.5 V 1: 0.6 V 2: 0.7 V 3: 0.8 V.
  [3:2] TOUCH_DRANGE — TOUCH attenuation.
0x10C TOUCH_SCAN_CTRL reset 0xF0000102 — Configure touch scan settings
  [31:28] TOUCH_OUT_RING — Select out one pad as guard_ring.
  [27:25] TOUCH_BUFDRV — Touch 14 buffer driver strength.
  [24:10] TOUCH_SCAN_PAD_MAP — Pad enable map for touch scan mode.
  [9] TOUCH_SHIELD_PAD_EN — Touch pad 14 will be used as shield_pad.
  [8] TOUCH_INACTIVE_CONNECTION — Inactive touch pads connect to 0: HighZ, 1: GND.
  [2] TOUCH_DENOISE_EN — Touch pad 0 will be used to denoise.
  [1:0] TOUCH_DENOISE_RES — Denoise resolution. 0: 12-bit; 1: 10-bit; 2: 8-bit; 3: 4-bit.
0x110 TOUCH_SLP_THRES reset 0x78000000 — Configure the settings of touch sleep pad
  [31:27] TOUCH_SLP_PAD — Select sleep pad.
  [26] TOUCH_SLP_APPROACH_EN — Enable the proximity mode of touch sleep pad.
  [21:0] TOUCH_SLP_TH — Set the threshold for touch sleep pad.
0x114 TOUCH_APPROACH access per field reset 0x50000000 — Configure touch approach settings
  [31:24] MEAS_TIME rw — Set the total measurement times for the pads in proximity mode. Range: 0 – 255.
  [23] TOUCH_SLP_CHANNEL_CLR wo — Clear touch sleep channel.
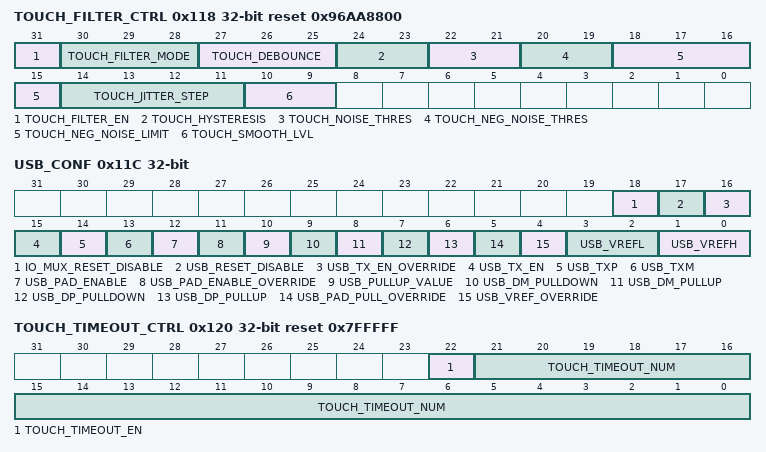
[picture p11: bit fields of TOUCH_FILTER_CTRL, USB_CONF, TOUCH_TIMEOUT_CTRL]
0x118 TOUCH_FILTER_CTRL reset 0x96AA8800 — Configure touch filter settings
  [31] TOUCH_FILTER_EN — Enable touch filter.
  [30:28] TOUCH_FILTER_MODE — Set filter mode. 0: IIR 1/2; 1: IIR 1/4; 2: IIR 1/8; 3: IIR 1/16; 4: IIR 1/32; 5: IIR 1/64; 6: IIR 1/128; 7: Jitter.
  [27:25] TOUCH_DEBOUNCE — Debounce counter.
  [24:23] TOUCH_HYSTERESIS
  [22:21] TOUCH_NOISE_THRES — Active noise threshold.
  [20:19] TOUCH_NEG_NOISE_THRES — Negative noise threshold.
  [18:15] TOUCH_NEG_NOISE_LIMIT — Negative threshold counter limit.
  [14:11] TOUCH_JITTER_STEP — Touch jitter step. Range: 0 – 15.
  [10:9] TOUCH_SMOOTH_LVL — 0: Raw data. 1: IIR1/2. 2: IIR1/4. 3: IIR1/8.
0x11C USB_CONF — configure usb control register
  [18] IO_MUX_RESET_DISABLE, [17] USB_RESET_DISABLE, [16] USB_TX_EN_OVERRIDE, [15] USB_TX_EN, [14] USB_TXP, [13] USB_TXM, [12] USB_PAD_ENABLE, [11] USB_PAD_ENABLE_OVERRIDE, [10] USB_PULLUP_VALUE, [9] USB_DM_PULLDOWN, [8] USB_DM_PULLUP, [7] USB_DP_PULLDOWN, [6] USB_DP_PULLUP, [5] USB_PAD_PULL_OVERRIDE, [4] USB_VREF_OVERRIDE, [3:2] USB_VREFL, [1:0] USB_VREFH
0x120 TOUCH_TIMEOUT_CTRL reset 0x7FFFFF — Configure touch timeout settings
  [22] TOUCH_TIMEOUT_EN — Enable touch timeout.
  [21:0] TOUCH_TIMEOUT_NUM — Set touch timeout threshold.
0x124 SLP_REJECT_CAUSE ro — Stores the reject-to-sleep cause.
  [16:0] REJECT_CAUSE
0x128 OPTION1 — RTC option register
  [0] FORCE_DOWNLOAD_BOOT — Set this bit to force the chip to boot from the download mode.
0x12C SLP_WAKEUP_CAUSE ro — Stores the sleep-to-wakeup cause.
  [16:0] WAKEUP_CAUSE — Stores the wakeup cause.
0x130 ULP_CP_TIMER_1 reset 0xC800 — Configure sleep cycle of the timer
  [31:8] ULP_CP_TIMER_SLP_CYCLE — Set sleep cycles for ULP coprocessor timer
0x138 DATE reset 0x1906191
  [27:0] RTC_CNTL_DATE
